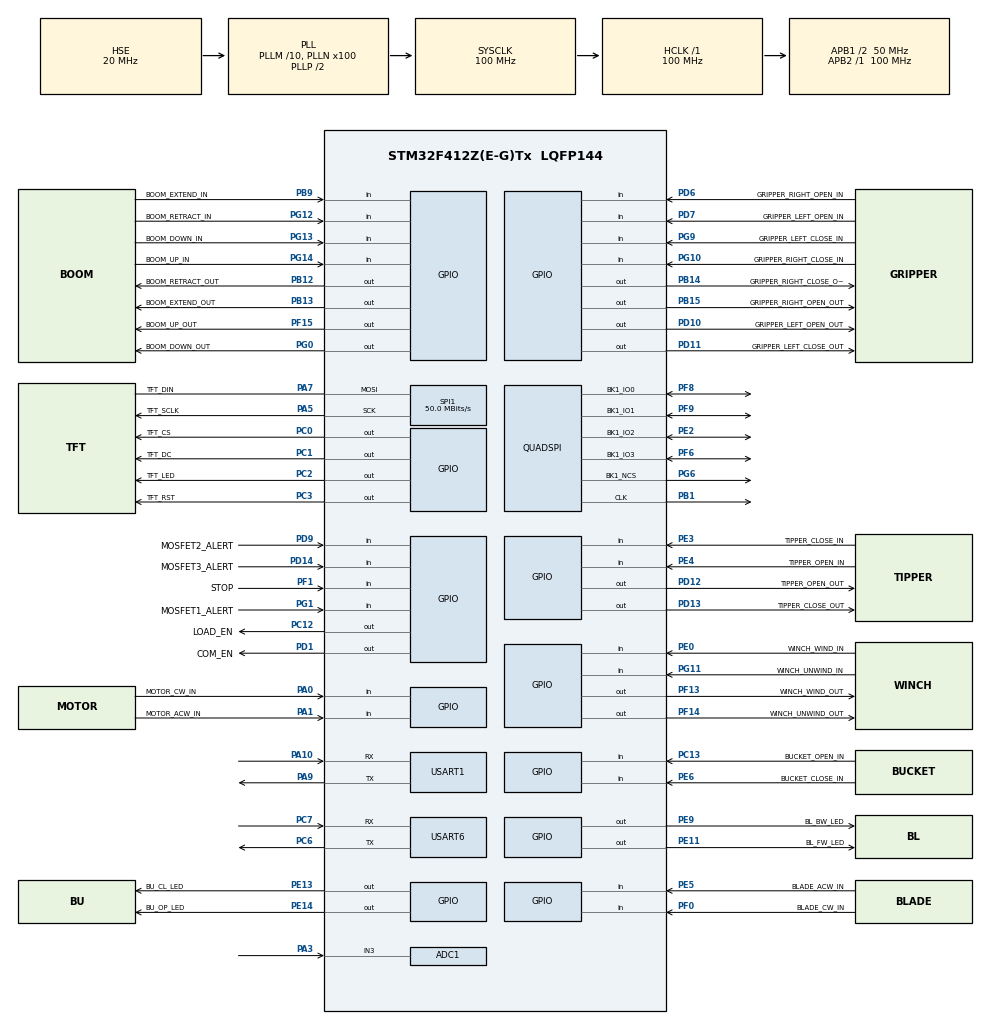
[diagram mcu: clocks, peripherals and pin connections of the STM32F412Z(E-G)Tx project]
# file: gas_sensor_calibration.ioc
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ADC1.Channel-0\#ChannelRegularConversion=ADC_CHANNEL_3
ADC1.NbrOfConversionFlag=1
ADC1.Rank-0\#ChannelRegularConversion=1
ADC1.SamplingTime-0\#ChannelRegularConversion=ADC_SAMPLETIME_3CYCLES
ADC1.master=1
Dma.Request0=USART1_RX
Dma.Request1=USART1_TX
Dma.USART1_RX.0.Direction=DMA_PERIPH_TO_MEMORY
Dma.USART1_RX.0.FIFOMode=DMA_FIFOMODE_DISABLE
Dma.USART1_RX.0.Instance=DMA2_Stream2
Dma.USART1_RX.0.MemDataAlignment=DMA_MDATAALIGN_BYTE
Dma.USART1_RX.0.MemInc=DMA_MINC_ENABLE
Dma.USART1_RX.0.Mode=DMA_NORMAL
Dma.USART1_RX.0.PeriphDataAlignment=DMA_PDATAALIGN_BYTE
Dma.USART1_RX.0.PeriphInc=DMA_PINC_DISABLE
Dma.USART1_RX.0.Priority=DMA_PRIORITY_HIGH
Dma.USART1_TX.1.Direction=DMA_MEMORY_TO_PERIPH
Dma.USART1_TX.1.FIFOMode=DMA_FIFOMODE_DISABLE
Dma.USART1_TX.1.Instance=DMA2_Stream7
Dma.USART1_TX.1.MemDataAlignment=DMA_MDATAALIGN_BYTE
Dma.USART1_TX.1.MemInc=DMA_MINC_ENABLE
Dma.USART1_TX.1.Mode=DMA_NORMAL
Dma.USART1_TX.1.PeriphDataAlignment=DMA_PDATAALIGN_BYTE
Dma.USART1_TX.1.PeriphInc=DMA_PINC_DISABLE
Dma.USART1_TX.1.Priority=DMA_PRIORITY_HIGH
Mcu.Family=STM32F4
Mcu.Name=STM32F412Z(E-G)Tx
Mcu.Package=LQFP144
NVIC.DMA2_Stream2_IRQn=true\:1\:0\:true\:false\:true\:false\:true\:true
NVIC.DMA2_Stream7_IRQn=true\:1\:0\:true\:false\:true\:false\:true\:true
NVIC.FPU_IRQn=true\:0\:0\:false\:false\:true\:true\:false\:true
NVIC.PriorityGroup=NVIC_PRIORITYGROUP_4
NVIC.RCC_IRQn=true\:0\:0\:false\:false\:true\:true\:false\:true
NVIC.TIM1_BRK_TIM9_IRQn=true\:2\:0\:true\:false\:true\:true\:true\:true
NVIC.TIM3_IRQn=true\:1\:0\:true\:false\:true\:true\:true\:true
NVIC.TIM5_IRQn=true\:0\:0\:false\:false\:true\:true\:true\:true
NVIC.TIM7_IRQn=true\:0\:0\:false\:false\:true\:true\:true\:true
NVIC.USART1_IRQn=true\:1\:0\:true\:false\:true\:true\:true\:true
PA0.GPIO_Label=MOTOR_CW_IN
PA0.GPIO_PuPd=GPIO_PULLUP
PA0.Signal=GPIO_Input
PA1.GPIO_Label=MOTOR_ACW_IN
PA1.GPIO_PuPd=GPIO_PULLUP
PA1.Signal=GPIO_Input
PA10.GPIO_Speed=GPIO_SPEED_FREQ_VERY_HIGH
PA10.Mode=Asynchronous
PA10.Signal=USART1_RX
PA13.Mode=Serial_Wire
PA13.Signal=SYS_JTMS-SWDIO
PA14.Mode=Serial_Wire
PA14.Signal=SYS_JTCK-SWCLK
PA3.Signal=ADCx_IN3
PA5.GPIO_Label=TFT_SCLK
PA5.Mode=Simplex_Bidirectional_Master
PA5.Signal=SPI1_SCK
PA7.GPIO_Label=TFT_DIN
PA7.Mode=Simplex_Bidirectional_Master
PA7.Signal=SPI1_MOSI
PA9.GPIO_Speed=GPIO_SPEED_FREQ_HIGH
PA9.Mode=Asynchronous
PA9.Signal=USART1_TX
PB1.Mode=Single Bank 1
PB1.Signal=QUADSPI_CLK
PB12.GPIO_Label=BOOM_RETRACT_OUT
PB12.Signal=GPIO_Output
PB13.GPIO_Label=BOOM_EXTEND_OUT
PB13.Signal=GPIO_Output
PB14.GPIO_Label=GRIPPER_RIGHT_CLOSE_OUT
PB14.Signal=GPIO_Output
PB15.GPIO_Label=GRIPPER_RIGHT_OPEN_OUT
PB15.Signal=GPIO_Output
PB9.GPIO_Label=BOOM_EXTEND_IN
PB9.GPIO_PuPd=GPIO_PULLUP
PB9.Signal=GPIO_Input
PC0.GPIO_Label=TFT_CS
PC0.Signal=GPIO_Output
PC1.GPIO_Label=TFT_DC
PC1.Signal=GPIO_Output
PC12.GPIO_Label=LOAD_EN
PC12.Signal=GPIO_Output
PC13.GPIO_Label=BUCKET_OPEN_IN
PC13.GPIO_PuPd=GPIO_PULLUP
PC13.Signal=GPIO_Input
PC14-OSC32_IN.Mode=LSE-External-Oscillator
PC14-OSC32_IN.Signal=RCC_OSC32_IN
PC15-OSC32_OUT.Mode=LSE-External-Oscillator
PC15-OSC32_OUT.Signal=RCC_OSC32_OUT
PC2.GPIO_Label=TFT_LED
PC2.Signal=GPIO_Output
PC3.GPIO_Label=TFT_RST
PC3.Signal=GPIO_Output
PC6.Mode=Asynchronous
PC6.Signal=USART6_TX
PC7.Mode=Asynchronous
PC7.Signal=USART6_RX
PD1.GPIO_Label=COM_EN
PD1.Signal=GPIO_Output
PD10.GPIO_Label=GRIPPER_LEFT_OPEN_OUT
PD10.Signal=GPIO_Output
PD11.GPIO_Label=GRIPPER_LEFT_CLOSE_OUT
PD11.Signal=GPIO_Output
PD12.GPIO_Label=TIPPER_OPEN_OUT
PD12.Signal=GPIO_Output
PD13.GPIO_Label=TIPPER_CLOSE_OUT
PD13.Signal=GPIO_Output
PD14.GPIO_Label=MOSFET3_ALERT
PD14.GPIO_PuPd=GPIO_PULLUP
PD14.Signal=GPIO_Input
PD6.GPIO_Label=GRIPPER_RIGHT_OPEN_IN
PD6.GPIO_PuPd=GPIO_PULLUP
PD6.Signal=GPIO_Input
PD7.GPIO_Label=GRIPPER_LEFT_OPEN_IN
PD7.GPIO_PuPd=GPIO_PULLUP
PD7.Signal=GPIO_Input
PD9.GPIO_Label=MOSFET2_ALERT
PD9.GPIO_PuPd=GPIO_PULLUP
PD9.Signal=GPIO_Input
PE0.GPIO_Label=WINCH_WIND_IN
PE0.GPIO_PuPd=GPIO_PULLUP
PE0.Signal=GPIO_Input
PE11.GPIO_Label=BL_FW_LED
PE11.GPIO_Speed=GPIO_SPEED_FREQ_HIGH
PE11.Signal=GPIO_Output
PE13.GPIO_Label=BU_CL_LED
PE13.GPIO_Speed=GPIO_SPEED_FREQ_HIGH
PE13.Signal=GPIO_Output
PE14.GPIO_Label=BU_OP_LED
PE14.GPIO_Speed=GPIO_SPEED_FREQ_HIGH
PE14.Signal=GPIO_Output
PE2.Mode=Single Bank 1
PE2.Signal=QUADSPI_BK1_IO2
PE3.GPIO_Label=TIPPER_CLOSE_IN
PE3.GPIO_PuPd=GPIO_PULLUP
PE3.Signal=GPIO_Input
PE4.GPIO_Label=TIPPER_OPEN_IN
PE4.GPIO_PuPd=GPIO_PULLUP
PE4.Signal=GPIO_Input
PE5.GPIO_Label=BLADE_ACW_IN
PE5.GPIO_PuPd=GPIO_PULLUP
PE5.Signal=GPIO_Input
PE6.GPIO_Label=BUCKET_CLOSE_IN
PE6.GPIO_PuPd=GPIO_PULLUP
PE6.Signal=GPIO_Input
PE9.GPIO_Label=BL_BW_LED
PE9.GPIO_Speed=GPIO_SPEED_FREQ_HIGH
PE9.Signal=GPIO_Output
PF0.GPIO_Label=BLADE_CW_IN
PF0.GPIO_PuPd=GPIO_PULLUP
PF0.Signal=GPIO_Input
PF1.GPIO_Label=STOP
PF1.GPIO_PuPd=GPIO_PULLUP
PF1.Signal=GPIO_Input
PF13.GPIO_Label=WINCH_WIND_OUT
PF13.Signal=GPIO_Output
PF14.GPIO_Label=WINCH_UNWIND_OUT
PF14.Signal=GPIO_Output
PF15.GPIO_Label=BOOM_UP_OUT
PF15.Signal=GPIO_Output
PF6.Mode=Single Bank 1
PF6.Signal=QUADSPI_BK1_IO3
PF8.Mode=Single Bank 1
PF8.Signal=QUADSPI_BK1_IO0
PF9.Mode=Single Bank 1
PF9.Signal=QUADSPI_BK1_IO1
PG0.GPIO_Label=BOOM_DOWN_OUT
PG0.Signal=GPIO_Output
PG1.GPIO_Label=MOSFET1_ALERT
PG1.GPIO_PuPd=GPIO_PULLUP
PG1.Signal=GPIO_Input
PG10.GPIO_Label=GRIPPER_RIGHT_CLOSE_IN
PG10.GPIO_PuPd=GPIO_PULLUP
PG10.Signal=GPIO_Input
PG11.GPIO_Label=WINCH_UNWIND_IN
PG11.GPIO_PuPd=GPIO_PULLUP
PG11.Signal=GPIO_Input
PG12.GPIO_Label=BOOM_RETRACT_IN
PG12.GPIO_PuPd=GPIO_PULLUP
PG12.Signal=GPIO_Input
PG13.GPIO_Label=BOOM_DOWN_IN
PG13.GPIO_PuPd=GPIO_PULLUP
PG13.Signal=GPIO_Input
PG14.GPIO_Label=BOOM_UP_IN
PG14.GPIO_PuPd=GPIO_PULLUP
PG14.Signal=GPIO_Input
PG6.Mode=Single Bank 1
PG6.Signal=QUADSPI_BK1_NCS
PG9.GPIO_Label=GRIPPER_LEFT_CLOSE_IN
PG9.GPIO_PuPd=GPIO_PULLUP
PG9.Signal=GPIO_Input
PH0\ -\ OSC_IN.Mode=HSE-External-Oscillator
PH0\ -\ OSC_IN.Signal=RCC_OSC_IN
PH1\ -\ OSC_OUT.Mode=HSE-External-Oscillator
PH1\ -\ OSC_OUT.Signal=RCC_OSC_OUT
ProjectManager.HeapSize=0x200
ProjectManager.StackSize=0x400
ProjectManager.TargetToolchain=STM32CubeIDE
QUADSPI.ClockPrescaler=1
QUADSPI.FifoThreshold=4
QUADSPI.FlashSize=21
RCC.AHBFreq_Value=100000000
RCC.APB1CLKDivider=RCC_HCLK_DIV2
RCC.APB1Freq_Value=50000000
RCC.APB1TimFreq_Value=100000000
RCC.APB2Freq_Value=100000000
RCC.APB2TimFreq_Value=100000000
RCC.CortexFreq_Value=100000000
RCC.HCLKFreq_Value=100000000
RCC.HSE_VALUE=20000000
RCC.PLLM=10
RCC.PLLN=100
RCC.PLLSourceVirtual=RCC_PLLSOURCE_HSE
RCC.RCC_RTC_Clock_Source=RCC_RTCCLKSOURCE_LSE
RCC.SYSCLKFreq_VALUE=100000000
RCC.SYSCLKSource=RCC_SYSCLKSOURCE_PLLCLK
RCC.USBFreq_Value=100000000
RCC.VCOOutputFreq_Value=200000000
RTC.HourFormat=RTC_HOURFORMAT_12
SH.ADCx_IN3.0=ADC1_IN3,IN3
SPI1.BaudRatePrescaler=SPI_BAUDRATEPRESCALER_2
SPI1.CalculateBaudRate=50.0 MBits/s
SPI1.Direction=SPI_DIRECTION_1LINE
SPI1.Mode=SPI_MODE_MASTER
SPI1.VirtualType=VM_MASTER
TIM3.Period=990-1
TIM3.Prescaler=9000-1
TIM5.Period=10000-1
TIM5.Prescaler=72-1
TIM7.Period=1000-1
TIM7.Prescaler=72-1
TIM9.Period=10000
TIM9.Prescaler=7200-1
USART1.VirtualMode=VM_ASYNC
USART6.VirtualMode=VM_ASYNC
VP_RTC_VS_RTC_Activate.Mode=RTC_Enabled
VP_RTC_VS_RTC_Calendar.Mode=RTC_Calendar
VP_TIM3_VS_ClockSourceINT.Mode=Internal
VP_TIM5_VS_ClockSourceINT.Mode=Internal
VP_TIM7_VS_ClockSourceINT.Mode=Enable_Timer
VP_TIM9_VS_ClockSourceINT.Mode=Internal
board=custom

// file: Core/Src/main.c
/* USER CODE BEGIN Header */
/**
  ******************************************************************************
  * @file           : main.c
  * @brief          : Main program body
  ******************************************************************************
  * @attention
  *
  * Copyright (c) 2025 STMicroelectronics.
  * All rights reserved.
  *
  * This software is licensed under terms that can be found in the LICENSE file
  * in the root directory of this software component.
  * If no LICENSE file comes with this software, it is provided AS-IS.
  *
  ******************************************************************************
  */
/* USER CODE END Header */
#include "main.h"

ADC_HandleTypeDef hadc1;

QSPI_HandleTypeDef hqspi;

RTC_HandleTypeDef hrtc;

SPI_HandleTypeDef hspi1;

TIM_HandleTypeDef htim3;
TIM_HandleTypeDef htim5;
TIM_HandleTypeDef htim7;
TIM_HandleTypeDef htim9;

UART_HandleTypeDef huart1;
UART_HandleTypeDef huart6;
DMA_HandleTypeDef hdma_usart1_rx;
DMA_HandleTypeDef hdma_usart1_tx;

void SystemClock_Config(void);
static void MX_GPIO_Init(void);
static void MX_DMA_Init(void);
static void MX_TIM3_Init(void);
static void MX_TIM9_Init(void);
static void MX_USART1_UART_Init(void);
static void MX_SPI1_Init(void);
static void MX_ADC1_Init(void);
static void MX_TIM7_Init(void);
static void MX_TIM5_Init(void);
static void MX_QUADSPI_Init(void);
static void MX_RTC_Init(void);
static void MX_USART6_UART_Init(void);

/* USER CODE BEGIN 0 */

#include "code_base/homosep_master/homosep_master_inc.h"
#include "code_base/homosep_master/homosep_master_inc.c"

//#include "test.h"

/* USER CODE END 0 */

int main(void)
{

  /* MCU Configuration--------------------------------------------------------*/

  /* Reset of all peripherals, Initializes the Flash interface and the Systick. */
  HAL_Init();

  /* Configure the system clock */
  SystemClock_Config();

  /* Initialize all configured peripherals */
  MX_GPIO_Init();
  MX_DMA_Init();
  MX_TIM3_Init();
  MX_TIM9_Init();
  MX_USART1_UART_Init();
  MX_SPI1_Init();
  MX_ADC1_Init();
  MX_TIM7_Init();
  MX_TIM5_Init();
  MX_QUADSPI_Init();
  MX_RTC_Init();
  MX_USART6_UART_Init();
  /* USER CODE BEGIN 2 */
 // HAL_GPIO_WritePin(GPIOC, LOAD_EN_Pin, GPIO_PIN_SET);
    hm_init();
    while (1)
    {
        hm_frame();
    };
  /* USER CODE END 2 */

  /* Infinite loop */
    while (1)
    {

    }
}

void SystemClock_Config(void)
{
  RCC_OscInitTypeDef RCC_OscInitStruct = {0};
  RCC_ClkInitTypeDef RCC_ClkInitStruct = {0};

  /** Configure the main internal regulator output voltage
  */
  __HAL_RCC_PWR_CLK_ENABLE();
  __HAL_PWR_VOLTAGESCALING_CONFIG(PWR_REGULATOR_VOLTAGE_SCALE1);

  /** Initializes the RCC Oscillators according to the specified parameters
  * in the RCC_OscInitTypeDef structure.
  */
  RCC_OscInitStruct.OscillatorType = RCC_OSCILLATORTYPE_HSE|RCC_OSCILLATORTYPE_LSE;
  RCC_OscInitStruct.HSEState = RCC_HSE_ON;
  RCC_OscInitStruct.LSEState = RCC_LSE_ON;
  RCC_OscInitStruct.PLL.PLLState = RCC_PLL_ON;
  RCC_OscInitStruct.PLL.PLLSource = RCC_PLLSOURCE_HSE;
  RCC_OscInitStruct.PLL.PLLM = 10;
  RCC_OscInitStruct.PLL.PLLN = 100;
  RCC_OscInitStruct.PLL.PLLP = RCC_PLLP_DIV2;
  RCC_OscInitStruct.PLL.PLLQ = 2;
  RCC_OscInitStruct.PLL.PLLR = 2;
  if (HAL_RCC_OscConfig(&RCC_OscInitStruct) != HAL_OK)
  {
    Error_Handler();
  }

  /** Initializes the CPU, AHB and APB buses clocks
  */
  RCC_ClkInitStruct.ClockType = RCC_CLOCKTYPE_HCLK|RCC_CLOCKTYPE_SYSCLK
                              |RCC_CLOCKTYPE_PCLK1|RCC_CLOCKTYPE_PCLK2;
  RCC_ClkInitStruct.SYSCLKSource = RCC_SYSCLKSOURCE_PLLCLK;
  RCC_ClkInitStruct.AHBCLKDivider = RCC_SYSCLK_DIV1;
  RCC_ClkInitStruct.APB1CLKDivider = RCC_HCLK_DIV2;
  RCC_ClkInitStruct.APB2CLKDivider = RCC_HCLK_DIV1;

  if (HAL_RCC_ClockConfig(&RCC_ClkInitStruct, FLASH_LATENCY_3) != HAL_OK)
  {
    Error_Handler();
  }
}

static void MX_ADC1_Init(void)
{

  ADC_ChannelConfTypeDef sConfig = {0};

  /** Configure the global features of the ADC (Clock, Resolution, Data Alignment and number of conversion)
  */
  hadc1.Instance = ADC1;
  hadc1.Init.ClockPrescaler = ADC_CLOCK_SYNC_PCLK_DIV4;
  hadc1.Init.Resolution = ADC_RESOLUTION_12B;
  hadc1.Init.ScanConvMode = DISABLE;
  hadc1.Init.ContinuousConvMode = DISABLE;
  hadc1.Init.DiscontinuousConvMode = DISABLE;
  hadc1.Init.ExternalTrigConvEdge = ADC_EXTERNALTRIGCONVEDGE_NONE;
  hadc1.Init.ExternalTrigConv = ADC_SOFTWARE_START;
  hadc1.Init.DataAlign = ADC_DATAALIGN_RIGHT;
  hadc1.Init.NbrOfConversion = 1;
  hadc1.Init.DMAContinuousRequests = DISABLE;
  hadc1.Init.EOCSelection = ADC_EOC_SINGLE_CONV;
  if (HAL_ADC_Init(&hadc1) != HAL_OK)
  {
    Error_Handler();
  }

  /** Configure for the selected ADC regular channel its corresponding rank in the sequencer and its sample time.
  */
  sConfig.Channel = ADC_CHANNEL_3;
  sConfig.Rank = 1;
  sConfig.SamplingTime = ADC_SAMPLETIME_3CYCLES;
  if (HAL_ADC_ConfigChannel(&hadc1, &sConfig) != HAL_OK)
  {
    Error_Handler();
  }

}

static void MX_QUADSPI_Init(void)
{

  /* QUADSPI parameter configuration*/
  hqspi.Instance = QUADSPI;
  hqspi.Init.ClockPrescaler = 1;
  hqspi.Init.FifoThreshold = 4;
  hqspi.Init.SampleShifting = QSPI_SAMPLE_SHIFTING_NONE;
  hqspi.Init.FlashSize = 21;
  hqspi.Init.ChipSelectHighTime = QSPI_CS_HIGH_TIME_1_CYCLE;
  hqspi.Init.ClockMode = QSPI_CLOCK_MODE_0;
  hqspi.Init.FlashID = QSPI_FLASH_ID_1;
  hqspi.Init.DualFlash = QSPI_DUALFLASH_DISABLE;
  if (HAL_QSPI_Init(&hqspi) != HAL_OK)
  {
    Error_Handler();
  }

}

static void MX_RTC_Init(void)
{

  RTC_TimeTypeDef sTime = {0};
  RTC_DateTypeDef sDate = {0};

  /** Initialize RTC Only
  */
  hrtc.Instance = RTC;
  hrtc.Init.HourFormat = RTC_HOURFORMAT_24;
  hrtc.Init.AsynchPrediv = 127;
  hrtc.Init.SynchPrediv = 255;
  hrtc.Init.OutPut = RTC_OUTPUT_DISABLE;
  hrtc.Init.OutPutPolarity = RTC_OUTPUT_POLARITY_HIGH;
  hrtc.Init.OutPutType = RTC_OUTPUT_TYPE_OPENDRAIN;
  if (HAL_RTC_Init(&hrtc) != HAL_OK)
  {
    Error_Handler();
  }

  /** Initialize RTC and set the Time and Date
  */

}

static void MX_SPI1_Init(void)
{

  /* SPI1 parameter configuration*/
  hspi1.Instance = SPI1;
  hspi1.Init.Mode = SPI_MODE_MASTER;
  hspi1.Init.Direction = SPI_DIRECTION_1LINE;
  hspi1.Init.DataSize = SPI_DATASIZE_8BIT;
  hspi1.Init.CLKPolarity = SPI_POLARITY_LOW;
  hspi1.Init.CLKPhase = SPI_PHASE_1EDGE;
  hspi1.Init.NSS = SPI_NSS_SOFT;
  hspi1.Init.BaudRatePrescaler = SPI_BAUDRATEPRESCALER_2;
  hspi1.Init.FirstBit = SPI_FIRSTBIT_MSB;
  hspi1.Init.TIMode = SPI_TIMODE_DISABLE;
  hspi1.Init.CRCCalculation = SPI_CRCCALCULATION_DISABLE;
  hspi1.Init.CRCPolynomial = 10;
  if (HAL_SPI_Init(&hspi1) != HAL_OK)
  {
    Error_Handler();
  }

}

static void MX_TIM3_Init(void)
{

  TIM_ClockConfigTypeDef sClockSourceConfig = {0};
  TIM_MasterConfigTypeDef sMasterConfig = {0};

  htim3.Instance = TIM3;
  htim3.Init.Prescaler = 9000-1;
  htim3.Init.CounterMode = TIM_COUNTERMODE_UP;
  htim3.Init.Period = 990-1;
  htim3.Init.ClockDivision = TIM_CLOCKDIVISION_DIV1;
  htim3.Init.AutoReloadPreload = TIM_AUTORELOAD_PRELOAD_DISABLE;
  if (HAL_TIM_Base_Init(&htim3) != HAL_OK)
  {
    Error_Handler();
  }
  sClockSourceConfig.ClockSource = TIM_CLOCKSOURCE_INTERNAL;
  if (HAL_TIM_ConfigClockSource(&htim3, &sClockSourceConfig) != HAL_OK)
  {
    Error_Handler();
  }
  sMasterConfig.MasterOutputTrigger = TIM_TRGO_RESET;
  sMasterConfig.MasterSlaveMode = TIM_MASTERSLAVEMODE_DISABLE;
  if (HAL_TIMEx_MasterConfigSynchronization(&htim3, &sMasterConfig) != HAL_OK)
  {
    Error_Handler();
  }

}

static void MX_TIM5_Init(void)
{

  TIM_ClockConfigTypeDef sClockSourceConfig = {0};
  TIM_MasterConfigTypeDef sMasterConfig = {0};

  htim5.Instance = TIM5;
  htim5.Init.Prescaler = 72-1;
  htim5.Init.CounterMode = TIM_COUNTERMODE_UP;
  htim5.Init.Period = 10000-1;
  htim5.Init.ClockDivision = TIM_CLOCKDIVISION_DIV1;
  htim5.Init.AutoReloadPreload = TIM_AUTORELOAD_PRELOAD_DISABLE;
  if (HAL_TIM_Base_Init(&htim5) != HAL_OK)
  {
    Error_Handler();
  }
  sClockSourceConfig.ClockSource = TIM_CLOCKSOURCE_INTERNAL;
  if (HAL_TIM_ConfigClockSource(&htim5, &sClockSourceConfig) != HAL_OK)
  {
    Error_Handler();
  }
  sMasterConfig.MasterOutputTrigger = TIM_TRGO_RESET;
  sMasterConfig.MasterSlaveMode = TIM_MASTERSLAVEMODE_DISABLE;
  if (HAL_TIMEx_MasterConfigSynchronization(&htim5, &sMasterConfig) != HAL_OK)
  {
    Error_Handler();
  }

}

static void MX_TIM7_Init(void)
{

  htim7.Instance = TIM7;
  htim7.Init.Prescaler = 72-1;
  htim7.Init.CounterMode = TIM_COUNTERMODE_UP;
  htim7.Init.Period = 1000-1;
  htim7.Init.AutoReloadPreload = TIM_AUTORELOAD_PRELOAD_DISABLE;
  if (HAL_TIM_Base_Init(&htim7) != HAL_OK)
  {
    Error_Handler();
  }

}

static void MX_TIM9_Init(void)
{

  TIM_ClockConfigTypeDef sClockSourceConfig = {0};

  htim9.Instance = TIM9;
  htim9.Init.Prescaler = 7200-1;
  htim9.Init.CounterMode = TIM_COUNTERMODE_UP;
  htim9.Init.Period = 10000;
  htim9.Init.ClockDivision = TIM_CLOCKDIVISION_DIV1;
  htim9.Init.AutoReloadPreload = TIM_AUTORELOAD_PRELOAD_DISABLE;
  if (HAL_TIM_Base_Init(&htim9) != HAL_OK)
  {
    Error_Handler();
  }
  sClockSourceConfig.ClockSource = TIM_CLOCKSOURCE_INTERNAL;
  if (HAL_TIM_ConfigClockSource(&htim9, &sClockSourceConfig) != HAL_OK)
  {
    Error_Handler();
  }

}

static void MX_USART1_UART_Init(void)
{

  huart1.Instance = USART1;
  huart1.Init.BaudRate = 115200;
  huart1.Init.WordLength = UART_WORDLENGTH_8B;
  huart1.Init.StopBits = UART_STOPBITS_1;
  huart1.Init.Parity = UART_PARITY_NONE;
  huart1.Init.Mode = UART_MODE_TX_RX;
  huart1.Init.HwFlowCtl = UART_HWCONTROL_NONE;
  huart1.Init.OverSampling = UART_OVERSAMPLING_16;
  if (HAL_UART_Init(&huart1) != HAL_OK)
  {
    Error_Handler();
  }

}

static void MX_USART6_UART_Init(void)
{

  huart6.Instance = USART6;
  huart6.Init.BaudRate = 115200;
  huart6.Init.WordLength = UART_WORDLENGTH_8B;
  huart6.Init.StopBits = UART_STOPBITS_1;
  huart6.Init.Parity = UART_PARITY_NONE;
  huart6.Init.Mode = UART_MODE_TX_RX;
  huart6.Init.HwFlowCtl = UART_HWCONTROL_NONE;
  huart6.Init.OverSampling = UART_OVERSAMPLING_16;
  if (HAL_UART_Init(&huart6) != HAL_OK)
  {
    Error_Handler();
  }

}

static void MX_DMA_Init(void)
{

  /* DMA controller clock enable */
  __HAL_RCC_DMA2_CLK_ENABLE();

  /* DMA interrupt init */
  /* DMA2_Stream2_IRQn interrupt configuration */
  HAL_NVIC_SetPriority(DMA2_Stream2_IRQn, 1, 0);
  HAL_NVIC_EnableIRQ(DMA2_Stream2_IRQn);
  /* DMA2_Stream7_IRQn interrupt configuration */
  HAL_NVIC_SetPriority(DMA2_Stream7_IRQn, 1, 0);
  HAL_NVIC_EnableIRQ(DMA2_Stream7_IRQn);

}

static void MX_GPIO_Init(void)
{
  GPIO_InitTypeDef GPIO_InitStruct = {0};

  /* GPIO Ports Clock Enable */
  __HAL_RCC_GPIOE_CLK_ENABLE();
  __HAL_RCC_GPIOC_CLK_ENABLE();
  __HAL_RCC_GPIOF_CLK_ENABLE();
  __HAL_RCC_GPIOH_CLK_ENABLE();
  __HAL_RCC_GPIOA_CLK_ENABLE();
  __HAL_RCC_GPIOB_CLK_ENABLE();
  __HAL_RCC_GPIOG_CLK_ENABLE();
  __HAL_RCC_GPIOD_CLK_ENABLE();

  /*Configure GPIO pin Output Level */
  HAL_GPIO_WritePin(GPIOC, TFT_CS_Pin|TFT_DC_Pin|TFT_LED_Pin|TFT_RST_Pin
                          |LOAD_EN_Pin, GPIO_PIN_RESET);

  /*Configure GPIO pin Output Level */
  HAL_GPIO_WritePin(GPIOF, WINCH_WIND_OUT_Pin|WINCH_UNWIND_OUT_Pin|BOOM_UP_OUT_Pin, GPIO_PIN_RESET);

  /*Configure GPIO pin Output Level */
  HAL_GPIO_WritePin(BOOM_DOWN_OUT_GPIO_Port, BOOM_DOWN_OUT_Pin, GPIO_PIN_RESET);

  /*Configure GPIO pin Output Level */
  HAL_GPIO_WritePin(GPIOE, BL_BW_LED_Pin|BL_FW_LED_Pin|BU_CL_LED_Pin|BU_OP_LED_Pin, GPIO_PIN_RESET);

  /*Configure GPIO pin Output Level */
  HAL_GPIO_WritePin(GPIOB, BOOM_RETRACT_OUT_Pin|BOOM_EXTEND_OUT_Pin|GRIPPER_RIGHT_CLOSE_OUT_Pin|GRIPPER_RIGHT_OPEN_OUT_Pin, GPIO_PIN_RESET);

  /*Configure GPIO pin Output Level */
  HAL_GPIO_WritePin(GPIOD, GRIPPER_LEFT_OPEN_OUT_Pin|GRIPPER_LEFT_CLOSE_OUT_Pin|TIPPER_OPEN_OUT_Pin|TIPPER_CLOSE_OUT_Pin
                          |COM_EN_Pin, GPIO_PIN_RESET);

  /*Configure GPIO pins : TIPPER_CLOSE_IN_Pin TIPPER_OPEN_IN_Pin BLADE_ACW_IN_Pin BUCKET_CLOSE_IN_Pin
                           WINCH_WIND_IN_Pin */
  GPIO_InitStruct.Pin = TIPPER_CLOSE_IN_Pin|TIPPER_OPEN_IN_Pin|BLADE_ACW_IN_Pin|BUCKET_CLOSE_IN_Pin
                          |WINCH_WIND_IN_Pin;
  GPIO_InitStruct.Mode = GPIO_MODE_INPUT;
  GPIO_InitStruct.Pull = GPIO_PULLUP;
  HAL_GPIO_Init(GPIOE, &GPIO_InitStruct);

  /*Configure GPIO pin : BUCKET_OPEN_IN_Pin */
  GPIO_InitStruct.Pin = BUCKET_OPEN_IN_Pin;
  GPIO_InitStruct.Mode = GPIO_MODE_INPUT;
  GPIO_InitStruct.Pull = GPIO_PULLUP;
  HAL_GPIO_Init(BUCKET_OPEN_IN_GPIO_Port, &GPIO_InitStruct);

  /*Configure GPIO pins : BLADE_CW_IN_Pin STOP_Pin */
  GPIO_InitStruct.Pin = BLADE_CW_IN_Pin|STOP_Pin;
  GPIO_InitStruct.Mode = GPIO_MODE_INPUT;
  GPIO_InitStruct.Pull = GPIO_PULLUP;
  HAL_GPIO_Init(GPIOF, &GPIO_InitStruct);

  /*Configure GPIO pins : TFT_CS_Pin TFT_DC_Pin TFT_LED_Pin TFT_RST_Pin
                           LOAD_EN_Pin */
  GPIO_InitStruct.Pin = TFT_CS_Pin|TFT_DC_Pin|TFT_LED_Pin|TFT_RST_Pin
                          |LOAD_EN_Pin;
  GPIO_InitStruct.Mode = GPIO_MODE_OUTPUT_PP;
  GPIO_InitStruct.Pull = GPIO_NOPULL;
  GPIO_InitStruct.Speed = GPIO_SPEED_FREQ_LOW;
  HAL_GPIO_Init(GPIOC, &GPIO_InitStruct);

  /*Configure GPIO pins : MOTOR_CW_IN_Pin MOTOR_ACW_IN_Pin */
  GPIO_InitStruct.Pin = MOTOR_CW_IN_Pin|MOTOR_ACW_IN_Pin;
  GPIO_InitStruct.Mode = GPIO_MODE_INPUT;
  GPIO_InitStruct.Pull = GPIO_PULLUP;
  HAL_GPIO_Init(GPIOA, &GPIO_InitStruct);

  /*Configure GPIO pins : WINCH_WIND_OUT_Pin WINCH_UNWIND_OUT_Pin BOOM_UP_OUT_Pin */
  GPIO_InitStruct.Pin = WINCH_WIND_OUT_Pin|WINCH_UNWIND_OUT_Pin|BOOM_UP_OUT_Pin;
  GPIO_InitStruct.Mode = GPIO_MODE_OUTPUT_PP;
  GPIO_InitStruct.Pull = GPIO_NOPULL;
  GPIO_InitStruct.Speed = GPIO_SPEED_FREQ_LOW;
  HAL_GPIO_Init(GPIOF, &GPIO_InitStruct);

  /*Configure GPIO pin : BOOM_DOWN_OUT_Pin */
  GPIO_InitStruct.Pin = BOOM_DOWN_OUT_Pin;
  GPIO_InitStruct.Mode = GPIO_MODE_OUTPUT_PP;
  GPIO_InitStruct.Pull = GPIO_NOPULL;
  GPIO_InitStruct.Speed = GPIO_SPEED_FREQ_LOW;
  HAL_GPIO_Init(BOOM_DOWN_OUT_GPIO_Port, &GPIO_InitStruct);

  /*Configure GPIO pins : MOSFET1_ALERT_Pin GRIPPER_LEFT_CLOSE_IN_Pin GRIPPER_RIGHT_CLOSE_IN_Pin WINCH_UNWIND_IN_Pin
                           BOOM_RETRACT_IN_Pin BOOM_DOWN_IN_Pin BOOM_UP_IN_Pin */
  GPIO_InitStruct.Pin = MOSFET1_ALERT_Pin|GRIPPER_LEFT_CLOSE_IN_Pin|GRIPPER_RIGHT_CLOSE_IN_Pin|WINCH_UNWIND_IN_Pin
                          |BOOM_RETRACT_IN_Pin|BOOM_DOWN_IN_Pin|BOOM_UP_IN_Pin;
  GPIO_InitStruct.Mode = GPIO_MODE_INPUT;
  GPIO_InitStruct.Pull = GPIO_PULLUP;
  HAL_GPIO_Init(GPIOG, &GPIO_InitStruct);

  /*Configure GPIO pins : BL_BW_LED_Pin BL_FW_LED_Pin BU_CL_LED_Pin BU_OP_LED_Pin */
  GPIO_InitStruct.Pin = BL_BW_LED_Pin|BL_FW_LED_Pin|BU_CL_LED_Pin|BU_OP_LED_Pin;
  GPIO_InitStruct.Mode = GPIO_MODE_OUTPUT_PP;
  GPIO_InitStruct.Pull = GPIO_NOPULL;
  GPIO_InitStruct.Speed = GPIO_SPEED_FREQ_HIGH;
  HAL_GPIO_Init(GPIOE, &GPIO_InitStruct);

  /*Configure GPIO pins : BOOM_RETRACT_OUT_Pin BOOM_EXTEND_OUT_Pin GRIPPER_RIGHT_CLOSE_OUT_Pin GRIPPER_RIGHT_OPEN_OUT_Pin */
  GPIO_InitStruct.Pin = BOOM_RETRACT_OUT_Pin|BOOM_EXTEND_OUT_Pin|GRIPPER_RIGHT_CLOSE_OUT_Pin|GRIPPER_RIGHT_OPEN_OUT_Pin;
  GPIO_InitStruct.Mode = GPIO_MODE_OUTPUT_PP;
  GPIO_InitStruct.Pull = GPIO_NOPULL;
  GPIO_InitStruct.Speed = GPIO_SPEED_FREQ_LOW;
  HAL_GPIO_Init(GPIOB, &GPIO_InitStruct);

  /*Configure GPIO pins : MOSFET2_ALERT_Pin MOSFET3_ALERT_Pin GRIPPER_RIGHT_OPEN_IN_Pin GRIPPER_LEFT_OPEN_IN_Pin */
  GPIO_InitStruct.Pin = MOSFET2_ALERT_Pin|MOSFET3_ALERT_Pin|GRIPPER_RIGHT_OPEN_IN_Pin|GRIPPER_LEFT_OPEN_IN_Pin;
  GPIO_InitStruct.Mode = GPIO_MODE_INPUT;
  GPIO_InitStruct.Pull = GPIO_PULLUP;
  HAL_GPIO_Init(GPIOD, &GPIO_InitStruct);

  /*Configure GPIO pins : GRIPPER_LEFT_OPEN_OUT_Pin GRIPPER_LEFT_CLOSE_OUT_Pin TIPPER_OPEN_OUT_Pin TIPPER_CLOSE_OUT_Pin
                           COM_EN_Pin */
  GPIO_InitStruct.Pin = GRIPPER_LEFT_OPEN_OUT_Pin|GRIPPER_LEFT_CLOSE_OUT_Pin|TIPPER_OPEN_OUT_Pin|TIPPER_CLOSE_OUT_Pin
                          |COM_EN_Pin;
  GPIO_InitStruct.Mode = GPIO_MODE_OUTPUT_PP;
  GPIO_InitStruct.Pull = GPIO_NOPULL;
  GPIO_InitStruct.Speed = GPIO_SPEED_FREQ_LOW;
  HAL_GPIO_Init(GPIOD, &GPIO_InitStruct);

  /*Configure GPIO pin : BOOM_EXTEND_IN_Pin */
  GPIO_InitStruct.Pin = BOOM_EXTEND_IN_Pin;
  GPIO_InitStruct.Mode = GPIO_MODE_INPUT;
  GPIO_InitStruct.Pull = GPIO_PULLUP;
  HAL_GPIO_Init(BOOM_EXTEND_IN_GPIO_Port, &GPIO_InitStruct);

}

void Error_Handler(void)
{
    __disable_irq();
    while (1)
    {
    }
}
